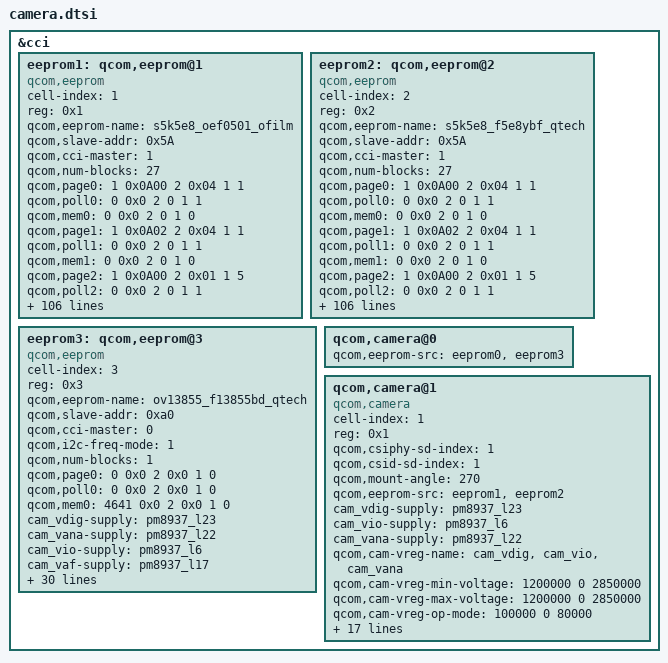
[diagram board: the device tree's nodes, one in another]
/* From stock msm8917-camera-sensor-mtp.dtsi */
&cci {
	eeprom1: qcom,eeprom@1 {
		cell-index = <1>;
		reg = <0x1>;
		qcom,eeprom-name = "s5k5e8_oef0501_ofilm";
		compatible = "qcom,eeprom";
		qcom,slave-addr = <0x5A>;
		qcom,cci-master = <1>;
		qcom,num-blocks = <27>;


		qcom,page0 = <1 0x0A00 2 0x04 1 1>;
		qcom,poll0 = <0 0x0 2 0 1 1>;
		qcom,mem0 = <0 0x0 2 0 1 0>;


		qcom,page1 = <1 0x0A02 2 0x04 1 1>;
		qcom,poll1 = <0 0x0 2 0 1 1>;
		qcom,mem1 = <0 0x0 2 0 1 0>;


		qcom,page2 = <1 0x0A00 2 0x01 1 5>;
		qcom,poll2 = <0 0x0 2 0 1 1>;
		qcom,mem2 = <16 0x0A34 2 0 1 0>;


		qcom,page3 = <1 0x0A00 2 0x04 1 1>;
		qcom,poll3 = <0 0x0 2 0 1 1>;
		qcom,mem3 = <0 0x0 2 0 1 0>;


		qcom,page4 = <1 0x0A02 2 0x05 1 1>;
		qcom,poll4 = <0 0x0 2 0 1 1>;
		qcom,mem4 = <0 0x0 2 0 1 0>;


		qcom,page5 = <1 0x0A00 2 0x01 1 5>;
		qcom,poll5 = <0 0x00 2 0 1 1>;
		qcom,mem5 = <64 0x0A04 2 0 1 0>;


		qcom,page6 = <1 0x0A00 2 0x04 1 1>;
		qcom,poll6 = <0 0x0 2 0 1 1>;
		qcom,mem6 = <0 0x0 2 0 1 0>;


		qcom,page7 = <1 0x0A02 2 0x06 1 1>;
		qcom,poll7= <0 0x0 2 0 1 1>;
		qcom,mem7 = <0 0x0 2 0 1 0>;


		qcom,page8= <1 0x0A00 2 0x01 1 5>;
		qcom,poll8 = <0 0x00 2 0 1 1>;
		qcom,mem8 = <64 0x0A04 2 0 1 0>;


		qcom,page9 = <1 0x0A00 2 0x04 1 1>;
		qcom,poll9 = <0 0x0 2 0 1 1>;
		qcom,mem9 = <0 0x0 2 0 1 0>;


		qcom,page10 = <1 0x0A02 2 0x07 1 1>;
		qcom,poll10= <0 0x0 2 0 1 1>;
		qcom,mem10 = <0 0x0 2 0 1 0>;


		qcom,page11 = <1 0x0A00 2 0x01 1 5>;
		qcom,poll11 = <0 0x00 2 0 1 1>;
		qcom,mem11 = <64 0x0A04 2 0 1 0>;


		qcom,page12 = <1 0x0A00 2 0x04 1 1>;
		qcom,poll12 = <0 0x0 2 0 1 1>;
		qcom,mem12 = <0 0x0 2 0 1 0>;


		qcom,page13 = <1 0x0A02 2 0x08 1 1>;
		qcom,poll13= <0 0x0 2 0 1 1>;
		qcom,mem13 = <0 0x0 2 0 1 0>;


		qcom,page14 = <1 0x0A00 2 0x01 1 5>;
		qcom,poll14 = <0 0x00 2 0 1 1>;
		qcom,mem14 = <64 0x0A04 2 0 1 0>;

		qcom,page15 = <1 0x0A00 2 0x04 1 1>;
		qcom,poll15 = <0 0x0 2 0 1 1>;
		qcom,mem15 = <0 0x0 2 0 1 0>;


		qcom,page16 = <1 0x0A02 2 0x09 1 1>;
		qcom,poll16= <0 0x0 2 0 1 1>;
		qcom,mem16 = <0 0x0 2 0 1 0>;


		qcom,page17 = <1 0x0A00 2 0x01 1 5>;
		qcom,poll17 = <0 0x00 2 0 1 1>;
		qcom,mem17 = <64 0x0A04 2 0 1 0>;


		qcom,page18 = <1 0x0A00 2 0x04 1 1>;
		qcom,poll18 = <0 0x0 2 0 1 1>;
		qcom,mem18 = <0 0x0 2 0 1 0>;


		qcom,page19 = <1 0x0A02 2 0x0A 1 1>;
		qcom,poll19= <0 0x0 2 0 1 1>;
		qcom,mem19 = <0 0x0 2 0 1 0>;


		qcom,page20 = <1 0x0A00 2 0x01 1 5>;
		qcom,poll20 = <0 0x0 2 0 1 1>;
		qcom,mem20 = <24 0x0A04 2 0 1 0>;


		qcom,page21= <1 0x0A00 2 0x04 1 1>;
		qcom,poll21 = <0 0x0 2 0 1 1>;
		qcom,mem21 = <0 0x0 2 0 1 0>;


		qcom,page22 = <1 0x0A02 2 0x0E 1 1>;
		qcom,poll22= <0 0x0 2 0 1 1>;
		qcom,mem22 = <0 0x0 2 0 1 0>;


		qcom,page23 = <1 0x0A00 2 0x01 1 5>;
		qcom,poll23 = <0 0x0 2 0 1 1>;
		qcom,mem23 = <64 0x0A04 2 0 1 0>;


		qcom,page24 = <1 0x0A00 2 0x04 1 1>;
		qcom,poll24 = <0 0x0 2 0 1 1>;
		qcom,mem24 = <0 0x0 2 0 1 0>;


		qcom,page25 = <1 0x0A02 2 0x0F 1 1>;
		qcom,poll25= <0 0x0 2 0 1 1>;
		qcom,mem25 = <0 0x0 2 0 1 0>;


		qcom,page26 = <1 0x0A00 2 0x01 1 5>;
		qcom,poll26 = <0 0x0 2 0 1 1>;
		qcom,mem26 = <39 0x0A04 2 0 1 0>;


		cam_vdig-supply = <&pm8937_l23>;
		cam_vio-supply = <&pm8937_l6>;
		cam_vana-supply = <&pm8937_l22>;
		qcom,cam-vreg-name = "cam_vdig", "cam_vio", "cam_vana";
		qcom,cam-vreg-min-voltage = <1200000 0 2850000>;
		qcom,cam-vreg-max-voltage = <1200000 0 2850000>;
		qcom,cam-vreg-op-mode = <200000 0 80000>;
		pinctrl-names = "cam_default", "cam_suspend";
		pinctrl-0 = <&cam_sensor_mclk1_default
				&cam_sensor_front1_default>;
		pinctrl-1 = <&cam_sensor_mclk1_sleep
				&cam_sensor_front1_sleep>;
		gpios = <&tlmm 27 0>,
			<&tlmm 40 0>,
			<&tlmm 39 0>;
		qcom,gpio-reset = <1>;
		qcom,gpio-standby = <2>;
		qcom,gpio-req-tbl-num = <0 1 2>;
		qcom,gpio-req-tbl-flags = <1 0 0>;
		qcom,gpio-req-tbl-label = "CAMIF_MCLK1",
			"CAM_RESET1",
			"CAM_STANDBY1";

		qcom,cam-power-seq-type = "sensor_gpio", "sensor_gpio", "sensor_vreg",
		"sensor_vreg", "sensor_vreg", "sensor_clk", "sensor_gpio", "sensor_gpio";
		qcom,cam-power-seq-val = "sensor_gpio_reset", "sensor_gpio_standby", "cam_vana", "cam_vdig","cam_vio",
		"sensor_cam_mclk","sensor_gpio_reset", "sensor_gpio_standby";
		qcom,cam-power-seq-cfg-val = <0 0 1 1 1 24000000 1 1>;
		qcom,cam-power-seq-delay = <1 1 5 5 5 1 10 10>;

		status = "ok";
		clocks = <&gcc MCLK1_CLK_SRC>,
			<&gcc GCC_CAMSS_MCLK1_CLK>;
		clock-names = "cam_src_clk", "cam_clk";
		qcom,clock-rates = <19200000 0>;
	};

	eeprom2: qcom,eeprom@2 {
		cell-index = <2>;
		reg = <0x2>;
		qcom,eeprom-name = "s5k5e8_f5e8ybf_qtech";
		compatible = "qcom,eeprom";
		qcom,slave-addr = <0x5A>;
		qcom,cci-master = <1>;
		qcom,num-blocks = <27>;


		qcom,page0 = <1 0x0A00 2 0x04 1 1>;
		qcom,poll0 = <0 0x0 2 0 1 1>;
		qcom,mem0 = <0 0x0 2 0 1 0>;


		qcom,page1 = <1 0x0A02 2 0x04 1 1>;
		qcom,poll1 = <0 0x0 2 0 1 1>;
		qcom,mem1 = <0 0x0 2 0 1 0>;


		qcom,page2 = <1 0x0A00 2 0x01 1 5>;
		qcom,poll2 = <0 0x0 2 0 1 1>;
		qcom,mem2 = <16 0x0A34 2 0 1 0>;


		qcom,page3 = <1 0x0A00 2 0x04 1 1>;
		qcom,poll3 = <0 0x0 2 0 1 1>;
		qcom,mem3 = <0 0x0 2 0 1 0>;


		qcom,page4 = <1 0x0A02 2 0x05 1 1>;
		qcom,poll4 = <0 0x0 2 0 1 1>;
		qcom,mem4 = <0 0x0 2 0 1 0>;


		qcom,page5 = <1 0x0A00 2 0x01 1 5>;
		qcom,poll5 = <0 0x00 2 0 1 1>;
		qcom,mem5 = <64 0x0A04 2 0 1 0>;


		qcom,page6 = <1 0x0A00 2 0x04 1 1>;
		qcom,poll6 = <0 0x0 2 0 1 1>;
		qcom,mem6 = <0 0x0 2 0 1 0>;


		qcom,page7 = <1 0x0A02 2 0x06 1 1>;
		qcom,poll7= <0 0x0 2 0 1 1>;
		qcom,mem7 = <0 0x0 2 0 1 0>;


		qcom,page8= <1 0x0A00 2 0x01 1 5>;
		qcom,poll8 = <0 0x00 2 0 1 1>;
		qcom,mem8 = <64 0x0A04 2 0 1 0>;


		qcom,page9 = <1 0x0A00 2 0x04 1 1>;
		qcom,poll9 = <0 0x0 2 0 1 1>;
		qcom,mem9 = <0 0x0 2 0 1 0>;


		qcom,page10 = <1 0x0A02 2 0x07 1 1>;
		qcom,poll10= <0 0x0 2 0 1 1>;
		qcom,mem10 = <0 0x0 2 0 1 0>;


		qcom,page11 = <1 0x0A00 2 0x01 1 5>;
		qcom,poll11 = <0 0x00 2 0 1 1>;
		qcom,mem11 = <64 0x0A04 2 0 1 0>;


		qcom,page12 = <1 0x0A00 2 0x04 1 1>;
		qcom,poll12 = <0 0x0 2 0 1 1>;
		qcom,mem12 = <0 0x0 2 0 1 0>;


		qcom,page13 = <1 0x0A02 2 0x08 1 1>;
		qcom,poll13= <0 0x0 2 0 1 1>;
		qcom,mem13 = <0 0x0 2 0 1 0>;


		qcom,page14 = <1 0x0A00 2 0x01 1 5>;
		qcom,poll14 = <0 0x00 2 0 1 1>;
		qcom,mem14 = <64 0x0A04 2 0 1 0>;

		qcom,page15 = <1 0x0A00 2 0x04 1 1>;
		qcom,poll15 = <0 0x0 2 0 1 1>;
		qcom,mem15 = <0 0x0 2 0 1 0>;


		qcom,page16 = <1 0x0A02 2 0x09 1 1>;
		qcom,poll16= <0 0x0 2 0 1 1>;
		qcom,mem16 = <0 0x0 2 0 1 0>;


		qcom,page17 = <1 0x0A00 2 0x01 1 5>;
		qcom,poll17 = <0 0x00 2 0 1 1>;
		qcom,mem17 = <64 0x0A04 2 0 1 0>;


		qcom,page18 = <1 0x0A00 2 0x04 1 1>;
		qcom,poll18 = <0 0x0 2 0 1 1>;
		qcom,mem18 = <0 0x0 2 0 1 0>;


		qcom,page19 = <1 0x0A02 2 0x0A 1 1>;
		qcom,poll19= <0 0x0 2 0 1 1>;
		qcom,mem19 = <0 0x0 2 0 1 0>;


		qcom,page20 = <1 0x0A00 2 0x01 1 5>;
		qcom,poll20 = <0 0x0 2 0 1 1>;
		qcom,mem20 = <24 0x0A04 2 0 1 0>;


		qcom,page21= <1 0x0A00 2 0x04 1 1>;
		qcom,poll21 = <0 0x0 2 0 1 1>;
		qcom,mem21 = <0 0x0 2 0 1 0>;


		qcom,page22 = <1 0x0A02 2 0x0E 1 1>;
		qcom,poll22= <0 0x0 2 0 1 1>;
		qcom,mem22 = <0 0x0 2 0 1 0>;


		qcom,page23 = <1 0x0A00 2 0x01 1 5>;
		qcom,poll23 = <0 0x0 2 0 1 1>;
		qcom,mem23 = <64 0x0A04 2 0 1 0>;


		qcom,page24 = <1 0x0A00 2 0x04 1 1>;
		qcom,poll24 = <0 0x0 2 0 1 1>;
		qcom,mem24 = <0 0x0 2 0 1 0>;


		qcom,page25 = <1 0x0A02 2 0x0F 1 1>;
		qcom,poll25= <0 0x0 2 0 1 1>;
		qcom,mem25 = <0 0x0 2 0 1 0>;


		qcom,page26 = <1 0x0A00 2 0x01 1 5>;
		qcom,poll26 = <0 0x0 2 0 1 1>;
		qcom,mem26 = <25 0x0A04 2 0 1 0>;


		cam_vdig-supply = <&pm8937_l23>;
		cam_vio-supply = <&pm8937_l6>;
		cam_vana-supply = <&pm8937_l22>;
		qcom,cam-vreg-name = "cam_vdig", "cam_vio", "cam_vana";
		qcom,cam-vreg-min-voltage = <1200000 0 2850000>;
		qcom,cam-vreg-max-voltage = <1200000 0 2850000>;
		qcom,cam-vreg-op-mode = <200000 0 80000>;
		pinctrl-names = "cam_default", "cam_suspend";
		pinctrl-0 = <&cam_sensor_mclk1_default
				&cam_sensor_front1_default>;
		pinctrl-1 = <&cam_sensor_mclk1_sleep
				&cam_sensor_front1_sleep>;
		gpios = <&tlmm 27 0>,
			<&tlmm 40 0>,
			<&tlmm 39 0>;
		qcom,gpio-reset = <1>;
		qcom,gpio-standby = <2>;
		qcom,gpio-req-tbl-num = <0 1 2>;
		qcom,gpio-req-tbl-flags = <1 0 0>;
		qcom,gpio-req-tbl-label = "CAMIF_MCLK1",
			"CAM_RESET1",
			"CAM_STANDBY1";

		qcom,cam-power-seq-type = "sensor_gpio", "sensor_gpio", "sensor_vreg",
		"sensor_vreg", "sensor_vreg", "sensor_clk", "sensor_gpio", "sensor_gpio";
		qcom,cam-power-seq-val = "sensor_gpio_reset", "sensor_gpio_standby", "cam_vana", "cam_vdig","cam_vio",
		"sensor_cam_mclk","sensor_gpio_reset", "sensor_gpio_standby";
		qcom,cam-power-seq-cfg-val = <0 0 1 1 1 24000000 1 1>;
		qcom,cam-power-seq-delay = <1 1 5 5 5 1 10 10>;

		status = "ok";
		clocks = <&gcc MCLK1_CLK_SRC>,
			<&gcc GCC_CAMSS_MCLK1_CLK>;
		clock-names = "cam_src_clk", "cam_clk";
		qcom,clock-rates = <19200000 0>;
	};

	eeprom3: qcom,eeprom@3 {
		cell-index = <3>;
		compatible = "qcom,eeprom";
		reg = <0x3>;
		qcom,eeprom-name = "ov13855_f13855bd_qtech";
		qcom,slave-addr = <0xa0>;
		qcom,cci-master = <0>;
		qcom,i2c-freq-mode = <1>;
		qcom,num-blocks = <1>;

		qcom,page0 = <0 0x0 2 0x0 1 0>;
		qcom,poll0 = <0 0x0 2 0x0 1 0>;
		qcom,mem0 = <4641 0x0 2 0x0 1 0>;

		cam_vdig-supply = <&pm8937_l23>;
		cam_vana-supply = <&pm8937_l22>;
		cam_vio-supply = <&pm8937_l6>;
		cam_vaf-supply = <&pm8937_l17>;
		qcom,cam-vreg-name = "cam_vdig","cam_vio", "cam_vana","cam_vaf";
		qcom,cam-vreg-min-voltage = <1200000 0 2850000 2850000>;
		qcom,cam-vreg-max-voltage = <1200000 0 2850000 2850000>;
		qcom,cam-vreg-op-mode = <100000 0 800000 800000>;
		pinctrl-names = "cam_default", "cam_suspend";
		pinctrl-0 = <&cam_sensor_mclk0_default
				&cam_sensor_rear_default>;
		pinctrl-1 = <&cam_sensor_mclk0_sleep &cam_sensor_rear_sleep>;
		gpios = <&tlmm 26 0>,
			<&tlmm 36 0>,
			<&tlmm 35 0>;
		qcom,gpio-reset = <1>;
		qcom,gpio-standby = <2>;
		qcom,gpio-req-tbl-num = <0 1 2>;
		qcom,gpio-req-tbl-flags = <1 0 0>;
		qcom,gpio-req-tbl-label = "CAMIF_MCLK0",
			"CAM_RESET0",
			"CAM_STANDBY0";
		qcom,cam-power-seq-type ="sensor_vreg","sensor_vreg","sensor_vreg","sensor_vreg","sensor_clk",
					"sensor_gpio","sensor_gpio";
		qcom,cam-power-seq-val ="cam_vdig","cam_vana","cam_vio","cam_vaf","sensor_cam_mclk",
					 "sensor_gpio_reset","sensor_gpio_standby";
		qcom,cam-power-seq-cfg-val = <1 1 1 1 24000000 1 1>;
		qcom,cam-power-seq-delay = <0 0 0 0 5 5 5>;
		status = "ok";
		clocks = <&gcc MCLK0_CLK_SRC>,
				<&gcc GCC_CAMSS_MCLK0_CLK>;
		clock-names = "cam_src_clk", "cam_clk";
		qcom,clock-rates = <19200000 0>;
	};

	qcom,camera@0 {
		qcom,eeprom-src = <&eeprom0 &eeprom3>;
	};

	qcom,camera@1 {
		cell-index = <1>;
		compatible = "qcom,camera";
		reg = <0x1>;
		qcom,csiphy-sd-index = <1>;
		qcom,csid-sd-index = <1>;
		qcom,mount-angle = <270>;
		qcom,eeprom-src = <&eeprom1 &eeprom2>;
		cam_vdig-supply = <&pm8937_l23>;
		cam_vio-supply = <&pm8937_l6>;
		cam_vana-supply = <&pm8937_l22>;
		qcom,cam-vreg-name = "cam_vdig", "cam_vio", "cam_vana";
		qcom,cam-vreg-min-voltage = <1200000 0 2850000>;
		qcom,cam-vreg-max-voltage = <1200000 0 2850000>;
		qcom,cam-vreg-op-mode = <100000 0 80000>;
		pinctrl-names = "cam_default", "cam_suspend";
		pinctrl-0 = <&cam_sensor_mclk1_default
				&cam_sensor_front1_default>;
		pinctrl-1 = <&cam_sensor_mclk1_sleep
				&cam_sensor_front1_sleep>;
		gpios = <&tlmm 27 0>,
			<&tlmm 40 0>,
			<&tlmm 39 0>;
		qcom,gpio-reset = <1>;
		qcom,gpio-standby = <2>;
		qcom,gpio-req-tbl-num = <0 1 2>;
		qcom,gpio-req-tbl-flags = <1 0 0>;
		qcom,gpio-req-tbl-label = "CAMIF_MCLK1",
			"CAM_RESET1",
			"CAM_STANDBY1";
		qcom,sensor-position = <1>;
		qcom,sensor-mode = <0>;
		qcom,cci-master = <1>;
		clocks = <&gcc MCLK1_CLK_SRC>,
				<&gcc GCC_CAMSS_MCLK1_CLK>;
		clock-names = "cam_src_clk", "cam_clk";
		qcom,clock-rates = <24000000 0>;
	};
};
